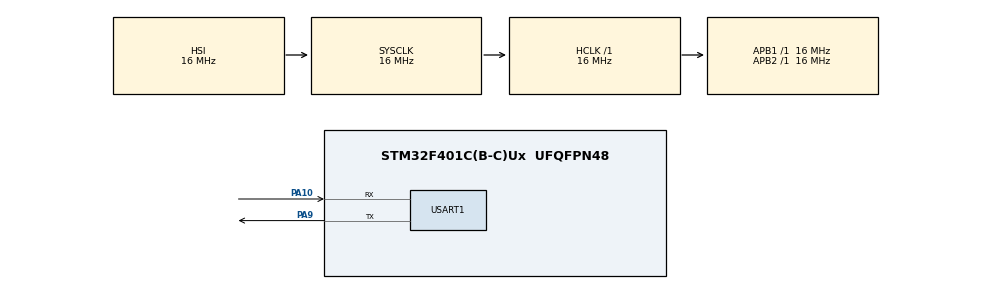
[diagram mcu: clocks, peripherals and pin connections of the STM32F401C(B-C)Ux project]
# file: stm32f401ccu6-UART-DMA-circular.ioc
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Dma.Request0=USART1_RX
Dma.USART1_RX.0.Direction=DMA_PERIPH_TO_MEMORY
Dma.USART1_RX.0.FIFOMode=DMA_FIFOMODE_DISABLE
Dma.USART1_RX.0.Instance=DMA2_Stream2
Dma.USART1_RX.0.MemDataAlignment=DMA_MDATAALIGN_BYTE
Dma.USART1_RX.0.MemInc=DMA_MINC_ENABLE
Dma.USART1_RX.0.Mode=DMA_CIRCULAR
Dma.USART1_RX.0.PeriphDataAlignment=DMA_PDATAALIGN_BYTE
Dma.USART1_RX.0.PeriphInc=DMA_PINC_DISABLE
Dma.USART1_RX.0.Priority=DMA_PRIORITY_LOW
Mcu.Family=STM32F4
Mcu.Name=STM32F401C(B-C)Ux
Mcu.Package=UFQFPN48
NVIC.DMA2_Stream2_IRQn=true\:0\:0\:false\:false\:true\:false\:true\:true
NVIC.PriorityGroup=NVIC_PRIORITYGROUP_4
PA10.Mode=Asynchronous
PA10.Signal=USART1_RX
PA13.Mode=Serial_Wire
PA13.Signal=SYS_JTMS-SWDIO
PA14.Mode=Serial_Wire
PA14.Signal=SYS_JTCK-SWCLK
PA9.Mode=Asynchronous
PA9.Signal=USART1_TX
PH0\ -\ OSC_IN.Mode=HSE-External-Oscillator
PH0\ -\ OSC_IN.Signal=RCC_OSC_IN
PH1\ -\ OSC_OUT.Mode=HSE-External-Oscillator
PH1\ -\ OSC_OUT.Signal=RCC_OSC_OUT
ProjectManager.HeapSize=0x200
ProjectManager.StackSize=0x400
ProjectManager.TargetToolchain=STM32CubeIDE
RCC.AHBFreq_Value=16000000
RCC.APB1Freq_Value=16000000
RCC.APB2Freq_Value=16000000
RCC.CortexFreq_Value=16000000
RCC.HSE_VALUE=25000000
RCC.HSI_VALUE=16000000
RCC.LSE_VALUE=32768
RCC.SYSCLKFreq_VALUE=16000000
RCC.VCOOutputFreq_Value=192000000
USART1.VirtualMode=VM_ASYNC
board=custom

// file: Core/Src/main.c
/* USER CODE BEGIN Header */
/**
  ******************************************************************************
  * @file           : main.c
  * @brief          : Main program body
  ******************************************************************************
  * @attention
  *
  * Copyright (c) 2025 STMicroelectronics.
  * All rights reserved.
  *
  * This software is licensed under terms that can be found in the LICENSE file
  * in the root directory of this software component.
  * If no LICENSE file comes with this software, it is provided AS-IS.
  *
  ******************************************************************************
  */
/* USER CODE END Header */
#include "main.h"

/* USER CODE BEGIN Includes */
#include "stdio.h"
#include "string.h"

/* USER CODE END Includes */

/* USER CODE BEGIN PD */

#define UART_RX_BUFFER_SIZE 50 // maximum data we expect

uint8_t UART1_rx_buffer[UART_RX_BUFFER_SIZE] = {0}; // to hold the received message
uint16_t rx_data_len = 0; // length of the received data

/* USER CODE END PD */

UART_HandleTypeDef huart1;
DMA_HandleTypeDef hdma_usart1_rx;

void SystemClock_Config(void);
static void MX_GPIO_Init(void);
static void MX_DMA_Init(void);
static void MX_USART1_UART_Init(void);

int main(void)
{

  /* MCU Configuration--------------------------------------------------------*/

  /* Reset of all peripherals, Initializes the Flash interface and the Systick. */
  HAL_Init();

  /* Configure the system clock */
  SystemClock_Config();

  /* Initialize all configured peripherals */
  MX_GPIO_Init();
  MX_DMA_Init();
  MX_USART1_UART_Init();
  /* USER CODE BEGIN 2 */

  HAL_UARTEx_ReceiveToIdle_DMA(&huart1, UART1_rx_buffer, UART_RX_BUFFER_SIZE);
  /* USER CODE END 2 */

  /* Infinite loop */
  while (1)
  {

    /* USER CODE BEGIN 3 */

	  // nothing to do here
  }
  /* USER CODE END 3 */
}

void SystemClock_Config(void)
{
  RCC_OscInitTypeDef RCC_OscInitStruct = {0};
  RCC_ClkInitTypeDef RCC_ClkInitStruct = {0};

  /** Configure the main internal regulator output voltage
  */
  __HAL_RCC_PWR_CLK_ENABLE();
  __HAL_PWR_VOLTAGESCALING_CONFIG(PWR_REGULATOR_VOLTAGE_SCALE2);

  /** Initializes the RCC Oscillators according to the specified parameters
  * in the RCC_OscInitTypeDef structure.
  */
  RCC_OscInitStruct.OscillatorType = RCC_OSCILLATORTYPE_HSI;
  RCC_OscInitStruct.HSIState = RCC_HSI_ON;
  RCC_OscInitStruct.HSICalibrationValue = RCC_HSICALIBRATION_DEFAULT;
  RCC_OscInitStruct.PLL.PLLState = RCC_PLL_NONE;
  if (HAL_RCC_OscConfig(&RCC_OscInitStruct) != HAL_OK)
  {
    Error_Handler();
  }

  /** Initializes the CPU, AHB and APB buses clocks
  */
  RCC_ClkInitStruct.ClockType = RCC_CLOCKTYPE_HCLK|RCC_CLOCKTYPE_SYSCLK
                              |RCC_CLOCKTYPE_PCLK1|RCC_CLOCKTYPE_PCLK2;
  RCC_ClkInitStruct.SYSCLKSource = RCC_SYSCLKSOURCE_HSI;
  RCC_ClkInitStruct.AHBCLKDivider = RCC_SYSCLK_DIV1;
  RCC_ClkInitStruct.APB1CLKDivider = RCC_HCLK_DIV1;
  RCC_ClkInitStruct.APB2CLKDivider = RCC_HCLK_DIV1;

  if (HAL_RCC_ClockConfig(&RCC_ClkInitStruct, FLASH_LATENCY_0) != HAL_OK)
  {
    Error_Handler();
  }
}

static void MX_USART1_UART_Init(void)
{

  huart1.Instance = USART1;
  huart1.Init.BaudRate = 115200;
  huart1.Init.WordLength = UART_WORDLENGTH_8B;
  huart1.Init.StopBits = UART_STOPBITS_1;
  huart1.Init.Parity = UART_PARITY_NONE;
  huart1.Init.Mode = UART_MODE_TX_RX;
  huart1.Init.HwFlowCtl = UART_HWCONTROL_NONE;
  huart1.Init.OverSampling = UART_OVERSAMPLING_16;
  if (HAL_UART_Init(&huart1) != HAL_OK)
  {
    Error_Handler();
  }

}

static void MX_DMA_Init(void)
{

  /* DMA controller clock enable */
  __HAL_RCC_DMA2_CLK_ENABLE();

  /* DMA interrupt init */
  /* DMA2_Stream2_IRQn interrupt configuration */
  HAL_NVIC_SetPriority(DMA2_Stream2_IRQn, 0, 0);
  HAL_NVIC_EnableIRQ(DMA2_Stream2_IRQn);

}

static void MX_GPIO_Init(void)
{

  /* GPIO Ports Clock Enable */
  __HAL_RCC_GPIOH_CLK_ENABLE();
  __HAL_RCC_GPIOA_CLK_ENABLE();

}

/* USER CODE BEGIN 4 */

/**
 * called when idle event is received OR we receive the full data length
 * we can receive variable length of data
 */
void HAL_UARTEx_RxEventCallback(UART_HandleTypeDef *huart, uint16_t Size) {
	// check the size of the received stream
	rx_data_len = Size;
	static char buffer[UART_RX_BUFFER_SIZE] = {0};

	sprintf(buffer, "Size: %d\r\n", rx_data_len);
	HAL_UART_Transmit(&huart1, (uint8_t*) buffer, strlen(buffer), 500);

	// process it
	HAL_UART_Transmit(&huart1, UART1_rx_buffer, rx_data_len, 500);

	// restart the idle event check
	HAL_UARTEx_ReceiveToIdle_DMA(&huart1, UART1_rx_buffer, UART_RX_BUFFER_SIZE);

}

/* USER CODE END 4 */

void Error_Handler(void)
{
  __disable_irq();
  while (1)
  {
  }
}
